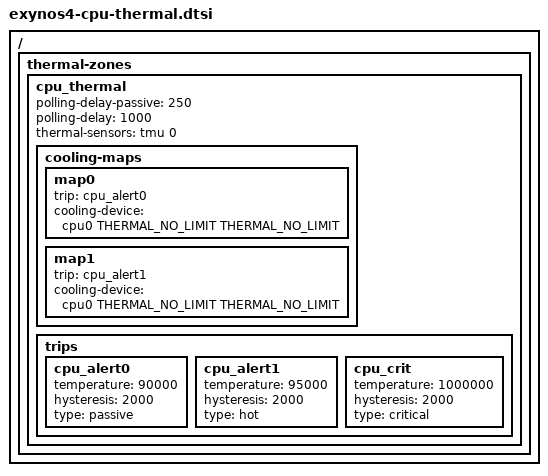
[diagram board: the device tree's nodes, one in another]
// SPDX-License-Identifier: GPL-2.0
/*
 * Device tree sources for Exynos4 thermal zone
 *
 * Copyright (c) 2014 Lukasz Majewski <l.majewski@samsung.com>
 */

#include <dt-bindings/thermal/thermal.h>

/ {
thermal-zones {
	cpu_thermal {
		/* milliseconds */
		polling-delay-passive = <250>;
		polling-delay = <1000>;
		thermal-sensors = <&tmu 0>;

		cooling-maps {
			map0 {
				trip = <&cpu_alert0>;
				cooling-device = <&cpu0 THERMAL_NO_LIMIT THERMAL_NO_LIMIT>;
			};

			map1 {
				trip = <&cpu_alert1>;
				cooling-device = <&cpu0 THERMAL_NO_LIMIT THERMAL_NO_LIMIT>;
			};
		};

		trips {
			cpu_alert0: cpu_alert0 {
				/* milliCelsius */
				temperature = <90000>;
				hysteresis = <2000>;
				type = "passive";
			};

			cpu_alert1: cpu_alert1 {
				/* milliCelsius */
				temperature = <95000>;
				hysteresis = <2000>;
				type = "hot";
			};

			cpu_crit: cpu_crit {
				/* milliCelsius */
				temperature = <1000000>;
				hysteresis = <2000>;
				type = "critical";
			};
		};
	};
};
};
